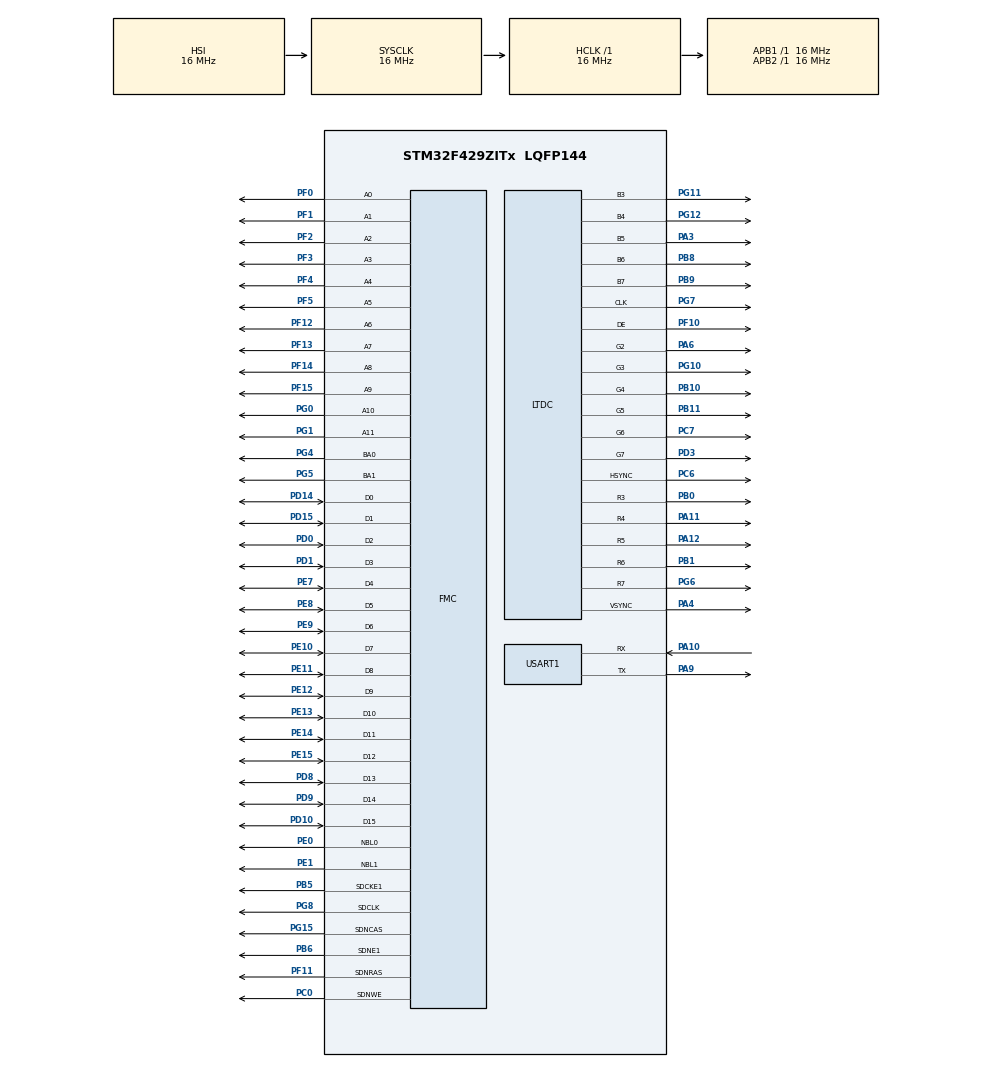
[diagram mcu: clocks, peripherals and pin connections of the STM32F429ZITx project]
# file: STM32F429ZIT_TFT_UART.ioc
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LTDC.Alpha_L0=255
LTDC.Alpha_L1=255
LTDC.Blue_L0=255
LTDC.FBStartAdress_L0=0xD0000000
LTDC.Green_L1=255
LTDC.ImageHeight_L0=240
LTDC.ImageWidth_L0=320
LTDC.Layers=0
LTDC.PixelFormat_L0=LTDC_PIXEL_FORMAT_RGB565
LTDC.WindowX0_L1=200
LTDC.WindowX1_L0=240
LTDC.WindowX1_L1=600
LTDC.WindowY0_L1=200
LTDC.WindowY1_L0=320
LTDC.WindowY1_L1=600
Mcu.Family=STM32F4
Mcu.Name=STM32F429ZITx
Mcu.Package=LQFP144
NVIC.LTDC_IRQn=true\:0\:0\:false\:false\:true\:true\:true
NVIC.PriorityGroup=NVIC_PRIORITYGROUP_4
PA10.Mode=Asynchronous
PA10.Signal=USART1_RX
PA11.GPIO_Speed=GPIO_SPEED_FREQ_VERY_HIGH
PA11.Mode=RGB565
PA11.Signal=LTDC_R4
PA12.GPIO_Speed=GPIO_SPEED_FREQ_VERY_HIGH
PA12.Mode=RGB565
PA12.Signal=LTDC_R5
PA3.GPIO_Speed=GPIO_SPEED_FREQ_VERY_HIGH
PA3.Mode=RGB565
PA3.Signal=LTDC_B5
PA4.GPIO_Speed=GPIO_SPEED_FREQ_VERY_HIGH
PA4.Mode=RGB565
PA4.Signal=LTDC_VSYNC
PA6.GPIO_Speed=GPIO_SPEED_FREQ_VERY_HIGH
PA6.Mode=RGB565
PA6.Signal=LTDC_G2
PA9.Mode=Asynchronous
PA9.Signal=USART1_TX
PB0.GPIO_Speed=GPIO_SPEED_FREQ_VERY_HIGH
PB0.Mode=RGB565
PB0.Signal=LTDC_R3
PB1.GPIO_Speed=GPIO_SPEED_FREQ_VERY_HIGH
PB1.Mode=RGB565
PB1.Signal=LTDC_R6
PB10.GPIO_Speed=GPIO_SPEED_FREQ_VERY_HIGH
PB10.Mode=RGB565
PB10.Signal=LTDC_G4
PB11.GPIO_Speed=GPIO_SPEED_FREQ_VERY_HIGH
PB11.Mode=RGB565
PB11.Signal=LTDC_G5
PB5.Mode=SdramChipSelect2_1
PB5.Signal=FMC_SDCKE1
PB6.Mode=SdramChipSelect2_1
PB6.Signal=FMC_SDNE1
PB8.GPIO_Speed=GPIO_SPEED_FREQ_VERY_HIGH
PB8.Mode=RGB565
PB8.Signal=LTDC_B6
PB9.GPIO_Speed=GPIO_SPEED_FREQ_VERY_HIGH
PB9.Mode=RGB565
PB9.Signal=LTDC_B7
PC0.Signal=FMC_SDNWE
PC6.GPIO_Speed=GPIO_SPEED_FREQ_VERY_HIGH
PC6.Mode=RGB565
PC6.Signal=LTDC_HSYNC
PC7.GPIO_Speed=GPIO_SPEED_FREQ_VERY_HIGH
PC7.Mode=RGB565
PC7.Signal=LTDC_G6
PD0.Signal=FMC_D2_DA2
PD1.Signal=FMC_D3_DA3
PD10.Signal=FMC_D15_DA15
PD14.Signal=FMC_D0_DA0
PD15.Signal=FMC_D1_DA1
PD3.GPIO_Speed=GPIO_SPEED_FREQ_VERY_HIGH
PD3.Mode=RGB565
PD3.Signal=LTDC_G7
PD8.Signal=FMC_D13_DA13
PD9.Signal=FMC_D14_DA14
PE0.Signal=FMC_NBL0
PE1.Signal=FMC_NBL1
PE10.Signal=FMC_D7_DA7
PE11.Signal=FMC_D8_DA8
PE12.Signal=FMC_D9_DA9
PE13.Signal=FMC_D10_DA10
PE14.Signal=FMC_D11_DA11
PE15.Signal=FMC_D12_DA12
PE7.Signal=FMC_D4_DA4
PE8.Signal=FMC_D5_DA5
PE9.Signal=FMC_D6_DA6
PF0.Signal=FMC_A0
PF1.Signal=FMC_A1
PF10.GPIO_Speed=GPIO_SPEED_FREQ_VERY_HIGH
PF10.Mode=RGB565
PF10.Signal=LTDC_DE
PF11.Signal=FMC_SDNRAS
PF12.Signal=FMC_A6
PF13.Signal=FMC_A7
PF14.Signal=FMC_A8
PF15.Signal=FMC_A9
PF2.Signal=FMC_A2
PF3.Signal=FMC_A3
PF4.Signal=FMC_A4
PF5.Signal=FMC_A5
PG0.Signal=FMC_A10
PG1.Signal=FMC_A11
PG10.GPIO_Speed=GPIO_SPEED_FREQ_VERY_HIGH
PG10.Mode=RGB565
PG10.Signal=LTDC_G3
PG11.GPIO_Speed=GPIO_SPEED_FREQ_VERY_HIGH
PG11.Mode=RGB565
PG11.Signal=LTDC_B3
PG12.GPIO_Speed=GPIO_SPEED_FREQ_VERY_HIGH
PG12.Mode=RGB565
PG12.Signal=LTDC_B4
PG15.Signal=FMC_SDNCAS
PG4.Signal=FMC_A14_BA0
PG5.Signal=FMC_A15_BA1
PG6.GPIO_Speed=GPIO_SPEED_FREQ_VERY_HIGH
PG6.Mode=RGB565
PG6.Signal=LTDC_R7
PG7.GPIO_Speed=GPIO_SPEED_FREQ_VERY_HIGH
PG7.Mode=RGB565
PG7.Signal=LTDC_CLK
PG8.Signal=FMC_SDCLK
ProjectManager.HeapSize=0x200
ProjectManager.StackSize=0x400
ProjectManager.TargetToolchain=Makefile
RCC.AHBFreq_Value=16000000
RCC.APB1Freq_Value=16000000
RCC.APB2Freq_Value=16000000
RCC.CortexFreq_Value=16000000
RCC.HSE_VALUE=25000000
RCC.HSI_VALUE=16000000
RCC.LSE_VALUE=32768
RCC.PLLSAIN=100
RCC.SYSCLKFreq_VALUE=16000000
RCC.VCOOutputFreq_Value=192000000
SH.FMC_A0.0=FMC_A0,12b-sda1
SH.FMC_A1.0=FMC_A1,12b-sda1
SH.FMC_A10.0=FMC_A10,12b-sda1
SH.FMC_A11.0=FMC_A11,12b-sda1
SH.FMC_A14_BA0.0=FMC_BA0,FourSdramBanks1
SH.FMC_A15_BA1.0=FMC_BA1,FourSdramBanks1
SH.FMC_A2.0=FMC_A2,12b-sda1
SH.FMC_A3.0=FMC_A3,12b-sda1
SH.FMC_A4.0=FMC_A4,12b-sda1
SH.FMC_A5.0=FMC_A5,12b-sda1
SH.FMC_A6.0=FMC_A6,12b-sda1
SH.FMC_A7.0=FMC_A7,12b-sda1
SH.FMC_A8.0=FMC_A8,12b-sda1
SH.FMC_A9.0=FMC_A9,12b-sda1
SH.FMC_D0_DA0.0=FMC_D0,sd-16b-d1
SH.FMC_D10_DA10.0=FMC_D10,sd-16b-d1
SH.FMC_D11_DA11.0=FMC_D11,sd-16b-d1
SH.FMC_D12_DA12.0=FMC_D12,sd-16b-d1
SH.FMC_D13_DA13.0=FMC_D13,sd-16b-d1
SH.FMC_D14_DA14.0=FMC_D14,sd-16b-d1
SH.FMC_D15_DA15.0=FMC_D15,sd-16b-d1
SH.FMC_D1_DA1.0=FMC_D1,sd-16b-d1
SH.FMC_D2_DA2.0=FMC_D2,sd-16b-d1
SH.FMC_D3_DA3.0=FMC_D3,sd-16b-d1
SH.FMC_D4_DA4.0=FMC_D4,sd-16b-d1
SH.FMC_D5_DA5.0=FMC_D5,sd-16b-d1
SH.FMC_D6_DA6.0=FMC_D6,sd-16b-d1
SH.FMC_D7_DA7.0=FMC_D7,sd-16b-d1
SH.FMC_D8_DA8.0=FMC_D8,sd-16b-d1
SH.FMC_D9_DA9.0=FMC_D9,sd-16b-d1
SH.FMC_NBL0.0=FMC_NBL0,Sd2ByteEnable1
SH.FMC_NBL1.0=FMC_NBL1,Sd2ByteEnable1
SH.FMC_SDCLK.0=FMC_SDCLK,12b-sda1
SH.FMC_SDNCAS.0=FMC_SDNCAS,12b-sda1
SH.FMC_SDNRAS.0=FMC_SDNRAS,12b-sda1
SH.FMC_SDNWE.0=FMC_SDNWE,12b-sda1
USART1.VirtualMode=VM_ASYNC
VP_DMA2D_VS_DMA2D.Mode=DMA2D_Activate
board=custom

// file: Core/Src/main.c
/* USER CODE BEGIN Header */
/**
  ******************************************************************************
  * @file           : main.c
  * @brief          : Main program body
  ******************************************************************************
  * @attention
  *
  * Copyright (c) 2022 STMicroelectronics.
  * All rights reserved.
  *
  * This software is licensed under terms that can be found in the LICENSE file
  * in the root directory of this software component.
  * If no LICENSE file comes with this software, it is provided AS-IS.
  *
  ******************************************************************************
  */
/* USER CODE END Header */
#include "main.h"
#include "stm32f429i_discovery.h"
#include "stm32f429i_discovery_lcd.h"
//#include "stm32f429i_discovery_sdram.h"
#include "string.h"

DMA2D_HandleTypeDef hdma2d;

LTDC_HandleTypeDef hltdc;

UART_HandleTypeDef huart1;

SDRAM_HandleTypeDef hsdram1;

void SystemClock_Config(void);
static void MX_GPIO_Init(void);
static void MX_LTDC_Init(void);
static void MX_USART1_UART_Init(void);
static void MX_DMA2D_Init(void);
static void MX_FMC_Init(void);

int main(void)
{

  /* MCU Configuration--------------------------------------------------------*/

  /* Reset of all peripherals, Initializes the Flash interface and the Systick. */
  HAL_Init();

  /* Configure the system clock */
  SystemClock_Config();

  /* Initialize all configured peripherals */
  MX_GPIO_Init();
  MX_LTDC_Init();
  MX_USART1_UART_Init();
  MX_DMA2D_Init();
  MX_FMC_Init();

  /* Infinite loop */
  /* USER CODE BEGIN WHILE */
  BSP_LCD_Init();
  BSP_LCD_LayerDefaultInit(LCD_BACKGROUND_LAYER,LCD_FRAME_BUFFER);
  BSP_LCD_LayerDefaultInit(LCD_FOREGROUND_LAYER,LCD_FRAME_BUFFER);
  BSP_LCD_SelectLayer(LCD_FOREGROUND_LAYER);
  BSP_LCD_DisplayOn();
  char pData[10];
  memset(pData,97,10);
  strcpy(pData,(char*)"hasib");
  while (1)
  {

	  HAL_UART_Receive(&huart1, (uint8_t*)pData,10,1000);
	  BSP_LCD_Clear(LCD_COLOR_WHITE);
	  BSP_LCD_ClearStringLine(1);
  	  BSP_LCD_SetTextColor(LCD_COLOR_BLACK);
  	  //BSP_LCD_DisplayStringAtLine(1,(uint8_t*)"pData");
  	  BSP_LCD_DisplayStringAtLine(1,(uint8_t*)pData);
 	  //BSP_LCD_DrawHLine(50, 50, 50);
 	  HAL_Delay(500);

    /* USER CODE END WHILE */

  }
}

void SystemClock_Config(void)
{
  RCC_OscInitTypeDef RCC_OscInitStruct = {0};
  RCC_ClkInitTypeDef RCC_ClkInitStruct = {0};

  /** Macro to configure the PLL multiplication factor
  */
  __HAL_RCC_PLL_PLLM_CONFIG(16);
  /** Macro to configure the PLL clock source
  */
  __HAL_RCC_PLL_PLLSOURCE_CONFIG(RCC_PLLSOURCE_HSI);
  /** Configure the main internal regulator output voltage
  */
  __HAL_RCC_PWR_CLK_ENABLE();
  __HAL_PWR_VOLTAGESCALING_CONFIG(PWR_REGULATOR_VOLTAGE_SCALE3);
  /** Initializes the RCC Oscillators according to the specified parameters
  * in the RCC_OscInitTypeDef structure.
  */
  RCC_OscInitStruct.OscillatorType = RCC_OSCILLATORTYPE_HSI;
  RCC_OscInitStruct.HSIState = RCC_HSI_ON;
  RCC_OscInitStruct.HSICalibrationValue = RCC_HSICALIBRATION_DEFAULT;
  RCC_OscInitStruct.PLL.PLLState = RCC_PLL_NONE;
  RCC_OscInitStruct.PLL.PLLSource = RCC_PLLSOURCE_HSI;
  if (HAL_RCC_OscConfig(&RCC_OscInitStruct) != HAL_OK)
  {
    Error_Handler();
  }
  /** Initializes the CPU, AHB and APB buses clocks
  */
  RCC_ClkInitStruct.ClockType = RCC_CLOCKTYPE_HCLK|RCC_CLOCKTYPE_SYSCLK
                              |RCC_CLOCKTYPE_PCLK1|RCC_CLOCKTYPE_PCLK2;
  RCC_ClkInitStruct.SYSCLKSource = RCC_SYSCLKSOURCE_HSI;
  RCC_ClkInitStruct.AHBCLKDivider = RCC_SYSCLK_DIV1;
  RCC_ClkInitStruct.APB1CLKDivider = RCC_HCLK_DIV1;
  RCC_ClkInitStruct.APB2CLKDivider = RCC_HCLK_DIV1;

  if (HAL_RCC_ClockConfig(&RCC_ClkInitStruct, FLASH_LATENCY_0) != HAL_OK)
  {
    Error_Handler();
  }
}

static void MX_DMA2D_Init(void)
{

  hdma2d.Instance = DMA2D;
  hdma2d.Init.Mode = DMA2D_M2M;
  hdma2d.Init.ColorMode = DMA2D_OUTPUT_ARGB8888;
  hdma2d.Init.OutputOffset = 0;
  hdma2d.LayerCfg[1].InputOffset = 0;
  hdma2d.LayerCfg[1].InputColorMode = DMA2D_INPUT_ARGB8888;
  hdma2d.LayerCfg[1].AlphaMode = DMA2D_NO_MODIF_ALPHA;
  hdma2d.LayerCfg[1].InputAlpha = 0;
  if (HAL_DMA2D_Init(&hdma2d) != HAL_OK)
  {
    Error_Handler();
  }
  if (HAL_DMA2D_ConfigLayer(&hdma2d, 1) != HAL_OK)
  {
    Error_Handler();
  }

}

static void MX_LTDC_Init(void)
{

  LTDC_LayerCfgTypeDef pLayerCfg = {0};

  hltdc.Instance = LTDC;
  hltdc.Init.HSPolarity = LTDC_HSPOLARITY_AL;
  hltdc.Init.VSPolarity = LTDC_VSPOLARITY_AL;
  hltdc.Init.DEPolarity = LTDC_DEPOLARITY_AL;
  hltdc.Init.PCPolarity = LTDC_PCPOLARITY_IPC;
  hltdc.Init.HorizontalSync = 7;
  hltdc.Init.VerticalSync = 3;
  hltdc.Init.AccumulatedHBP = 14;
  hltdc.Init.AccumulatedVBP = 5;
  hltdc.Init.AccumulatedActiveW = 654;
  hltdc.Init.AccumulatedActiveH = 485;
  hltdc.Init.TotalWidth = 660;
  hltdc.Init.TotalHeigh = 487;
  hltdc.Init.Backcolor.Blue = 0;
  hltdc.Init.Backcolor.Green = 0;
  hltdc.Init.Backcolor.Red = 0;
  if (HAL_LTDC_Init(&hltdc) != HAL_OK)
  {
    Error_Handler();
  }
  pLayerCfg.WindowX0 = 0;
  pLayerCfg.WindowX1 = 240;
  pLayerCfg.WindowY0 = 0;
  pLayerCfg.WindowY1 = 320;
  pLayerCfg.PixelFormat = LTDC_PIXEL_FORMAT_RGB565;
  pLayerCfg.Alpha = 255;
  pLayerCfg.Alpha0 = 0;
  pLayerCfg.BlendingFactor1 = LTDC_BLENDING_FACTOR1_CA;
  pLayerCfg.BlendingFactor2 = LTDC_BLENDING_FACTOR2_CA;
  pLayerCfg.FBStartAdress = 0xD0000000;
  pLayerCfg.ImageWidth = 320;
  pLayerCfg.ImageHeight = 240;
  pLayerCfg.Backcolor.Blue = 255;
  pLayerCfg.Backcolor.Green = 0;
  pLayerCfg.Backcolor.Red = 0;
  if (HAL_LTDC_ConfigLayer(&hltdc, &pLayerCfg, 0) != HAL_OK)
  {
    Error_Handler();
  }

}

static void MX_USART1_UART_Init(void)
{

  huart1.Instance = USART1;
  huart1.Init.BaudRate = 115200;
  huart1.Init.WordLength = UART_WORDLENGTH_8B;
  huart1.Init.StopBits = UART_STOPBITS_1;
  huart1.Init.Parity = UART_PARITY_NONE;
  huart1.Init.Mode = UART_MODE_TX_RX;
  huart1.Init.HwFlowCtl = UART_HWCONTROL_NONE;
  huart1.Init.OverSampling = UART_OVERSAMPLING_16;
  if (HAL_UART_Init(&huart1) != HAL_OK)
  {
    Error_Handler();
  }

}

/* FMC initialization function */
static void MX_FMC_Init(void)
{

  FMC_SDRAM_TimingTypeDef SdramTiming = {0};

  /** Perform the SDRAM1 memory initialization sequence
  */
  hsdram1.Instance = FMC_SDRAM_DEVICE;
  /* hsdram1.Init */
  hsdram1.Init.SDBank = FMC_SDRAM_BANK2;
  hsdram1.Init.ColumnBitsNumber = FMC_SDRAM_COLUMN_BITS_NUM_8;
  hsdram1.Init.RowBitsNumber = FMC_SDRAM_ROW_BITS_NUM_12;
  hsdram1.Init.MemoryDataWidth = FMC_SDRAM_MEM_BUS_WIDTH_16;
  hsdram1.Init.InternalBankNumber = FMC_SDRAM_INTERN_BANKS_NUM_4;
  hsdram1.Init.CASLatency = FMC_SDRAM_CAS_LATENCY_1;
  hsdram1.Init.WriteProtection = FMC_SDRAM_WRITE_PROTECTION_DISABLE;
  hsdram1.Init.SDClockPeriod = FMC_SDRAM_CLOCK_DISABLE;
  hsdram1.Init.ReadBurst = FMC_SDRAM_RBURST_DISABLE;
  hsdram1.Init.ReadPipeDelay = FMC_SDRAM_RPIPE_DELAY_0;
  /* SdramTiming */
  SdramTiming.LoadToActiveDelay = 16;
  SdramTiming.ExitSelfRefreshDelay = 16;
  SdramTiming.SelfRefreshTime = 16;
  SdramTiming.RowCycleDelay = 16;
  SdramTiming.WriteRecoveryTime = 16;
  SdramTiming.RPDelay = 16;
  SdramTiming.RCDDelay = 16;

  if (HAL_SDRAM_Init(&hsdram1, &SdramTiming) != HAL_OK)
  {
    Error_Handler( );
  }

}

static void MX_GPIO_Init(void)
{

  /* GPIO Ports Clock Enable */
  __HAL_RCC_GPIOF_CLK_ENABLE();
  __HAL_RCC_GPIOC_CLK_ENABLE();
  __HAL_RCC_GPIOA_CLK_ENABLE();
  __HAL_RCC_GPIOB_CLK_ENABLE();
  __HAL_RCC_GPIOG_CLK_ENABLE();
  __HAL_RCC_GPIOE_CLK_ENABLE();
  __HAL_RCC_GPIOD_CLK_ENABLE();

}

void Error_Handler(void)
{
  __disable_irq();
  while (1)
  {
  }
}
